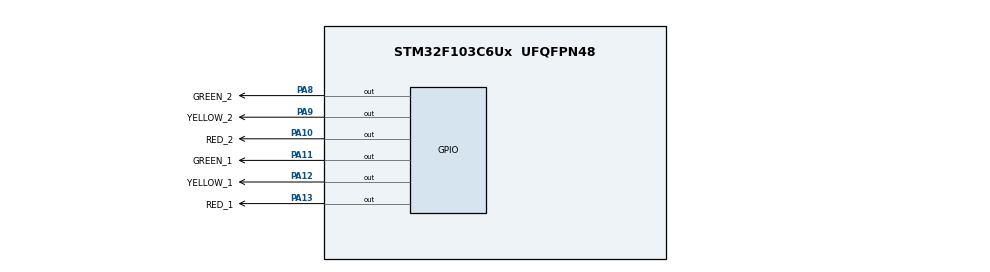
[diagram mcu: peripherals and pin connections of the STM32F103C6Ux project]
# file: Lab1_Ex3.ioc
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Mcu.Family=STM32F1
Mcu.Name=STM32F103C6Ux
Mcu.Package=UFQFPN48
NVIC.PriorityGroup=NVIC_PRIORITYGROUP_4
PA10.GPIO_Label=RED_2
PA10.Signal=GPIO_Output
PA11.GPIO_Label=GREEN_1
PA11.Signal=GPIO_Output
PA12.GPIO_Label=YELLOW_1
PA12.Signal=GPIO_Output
PA13.GPIO_Label=RED_1
PA13.Signal=GPIO_Output
PA8.GPIO_Label=GREEN_2
PA8.Signal=GPIO_Output
PA9.GPIO_Label=YELLOW_2
PA9.Signal=GPIO_Output
ProjectManager.HeapSize=0x200
ProjectManager.StackSize=0x400
ProjectManager.TargetToolchain=STM32CubeIDE
RCC.APB1Freq_Value=8000000
RCC.APB2Freq_Value=8000000
VP_SYS_VS_ND.Mode=No_Debug
board=custom

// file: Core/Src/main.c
/* USER CODE BEGIN Header */
/**
  ******************************************************************************
  * @file           : main.c
  * @brief          : Main program body
  ******************************************************************************
  * @attention
  *
  * <h2><center>&copy; Copyright (c) 2023 STMicroelectronics.
  * All rights reserved.</center></h2>
  *
  * This software component is licensed by ST under BSD 3-Clause license,
  * the "License"; You may not use this file except in compliance with the
  * License. You may obtain a copy of the License at:
  *                        opensource.org/licenses/BSD-3-Clause
  *
  ******************************************************************************
  */
/* USER CODE END Header */
#include "main.h"

void SystemClock_Config(void);
static void MX_GPIO_Init(void);

int main(void)
{

  /* MCU Configuration--------------------------------------------------------*/

  /* Reset of all peripherals, Initializes the Flash interface and the Systick. */
  HAL_Init();

  /* Configure the system clock */
  SystemClock_Config();

  /* Initialize all configured peripherals */
  MX_GPIO_Init();
  /* USER CODE BEGIN 2 */
  HAL_GPIO_WritePin ( GPIOA , GPIO_PIN_13 , GPIO_PIN_RESET ) ;//red1
  HAL_GPIO_WritePin ( GPIOA , GPIO_PIN_12 , GPIO_PIN_SET ) ;//yellow1
  HAL_GPIO_WritePin ( GPIOA , GPIO_PIN_11 , GPIO_PIN_SET ) ;//green1
  HAL_GPIO_WritePin ( GPIOA , GPIO_PIN_10 , GPIO_PIN_SET ) ;//red2
  HAL_GPIO_WritePin ( GPIOA , GPIO_PIN_9 , GPIO_PIN_SET ) ;//yellow2
  HAL_GPIO_WritePin ( GPIOA , GPIO_PIN_8 , GPIO_PIN_RESET ) ;//green2
   int count_1 = 5;
   int count_2 = 3;
   /* USER CODE END 2 */
   /* Infinite loop */
   /* USER CODE BEGIN WHILE */
   while (1)
   {
 	   if(count_1==0){
 		  GPIO_PinState pa13State = HAL_GPIO_ReadPin(GPIOA, GPIO_PIN_13);
 		  GPIO_PinState pa12State = HAL_GPIO_ReadPin(GPIOA, GPIO_PIN_12);
 		  GPIO_PinState pa11State = HAL_GPIO_ReadPin(GPIOA, GPIO_PIN_11);

 		  if (pa13State == GPIO_PIN_RESET){
 			  HAL_GPIO_TogglePin ( GPIOA , GPIO_PIN_13 | GPIO_PIN_11 );
 			  count_1 = 3;
 		  }
 		  if (pa12State == GPIO_PIN_RESET){
 			  HAL_GPIO_TogglePin ( GPIOA , GPIO_PIN_12 | GPIO_PIN_13 );
 			  count_1 = 5;
 		  }
 		  if (pa11State == GPIO_PIN_RESET){
 			  HAL_GPIO_TogglePin ( GPIOA , GPIO_PIN_11 | GPIO_PIN_12 );
 			  count_1 = 2;
 		  }
 	   }

 	 	   if(count_2==0){

 	 		  GPIO_PinState pa10State = HAL_GPIO_ReadPin(GPIOA, GPIO_PIN_10);
 	 		  GPIO_PinState pa9State = HAL_GPIO_ReadPin(GPIOA, GPIO_PIN_9);
 	 		  GPIO_PinState pa8State = HAL_GPIO_ReadPin(GPIOA, GPIO_PIN_8);

 	 		  if (pa10State == GPIO_PIN_RESET){
 	 			  HAL_GPIO_TogglePin ( GPIOA , GPIO_PIN_10 | GPIO_PIN_8 );
 	 			  count_2 = 3;
 	 		  }
 	 		  if (pa9State == GPIO_PIN_RESET){
 	 			  HAL_GPIO_TogglePin ( GPIOA , GPIO_PIN_9 | GPIO_PIN_10 );
 	 			  count_2 = 5;
 	 		  }
 	 		  if (pa8State == GPIO_PIN_RESET){
 	 			  HAL_GPIO_TogglePin ( GPIOA , GPIO_PIN_8 | GPIO_PIN_9 );
 	 			  count_2 = 2;
 	 		  }
 	   }
       count_1 = count_1 - 1 ;
       count_2 = count_2 - 1 ;
 	   HAL_Delay (1000) ;
   }
}

void SystemClock_Config(void)
{
  RCC_OscInitTypeDef RCC_OscInitStruct = {0};
  RCC_ClkInitTypeDef RCC_ClkInitStruct = {0};

  /** Initializes the RCC Oscillators according to the specified parameters
  * in the RCC_OscInitTypeDef structure.
  */
  RCC_OscInitStruct.OscillatorType = RCC_OSCILLATORTYPE_HSI;
  RCC_OscInitStruct.HSIState = RCC_HSI_ON;
  RCC_OscInitStruct.HSICalibrationValue = RCC_HSICALIBRATION_DEFAULT;
  RCC_OscInitStruct.PLL.PLLState = RCC_PLL_NONE;
  if (HAL_RCC_OscConfig(&RCC_OscInitStruct) != HAL_OK)
  {
    Error_Handler();
  }
  /** Initializes the CPU, AHB and APB buses clocks
  */
  RCC_ClkInitStruct.ClockType = RCC_CLOCKTYPE_HCLK|RCC_CLOCKTYPE_SYSCLK
                              |RCC_CLOCKTYPE_PCLK1|RCC_CLOCKTYPE_PCLK2;
  RCC_ClkInitStruct.SYSCLKSource = RCC_SYSCLKSOURCE_HSI;
  RCC_ClkInitStruct.AHBCLKDivider = RCC_SYSCLK_DIV1;
  RCC_ClkInitStruct.APB1CLKDivider = RCC_HCLK_DIV1;
  RCC_ClkInitStruct.APB2CLKDivider = RCC_HCLK_DIV1;

  if (HAL_RCC_ClockConfig(&RCC_ClkInitStruct, FLASH_LATENCY_0) != HAL_OK)
  {
    Error_Handler();
  }
}

static void MX_GPIO_Init(void)
{
  GPIO_InitTypeDef GPIO_InitStruct = {0};

  /* GPIO Ports Clock Enable */
  __HAL_RCC_GPIOA_CLK_ENABLE();
  __HAL_RCC_GPIOB_CLK_ENABLE();

  /*Configure GPIO pin Output Level */
  HAL_GPIO_WritePin(GPIOA, RED_1_Pin|YELLOW_1_Pin|GREEN_1_Pin|RED_2_Pin
                          |YELLOW_2_Pin, GPIO_PIN_RESET);

  /*Configure GPIO pin Output Level */
  HAL_GPIO_WritePin(GREEN_2_GPIO_Port, GREEN_2_Pin, GPIO_PIN_RESET);

  /*Configure GPIO pins : RED_1_Pin YELLOW_1_Pin GREEN_1_Pin RED_2_Pin
                           YELLOW_2_Pin */
  GPIO_InitStruct.Pin = RED_1_Pin|YELLOW_1_Pin|GREEN_1_Pin|RED_2_Pin
                          |YELLOW_2_Pin;
  GPIO_InitStruct.Mode = GPIO_MODE_OUTPUT_PP;
  GPIO_InitStruct.Pull = GPIO_NOPULL;
  GPIO_InitStruct.Speed = GPIO_SPEED_FREQ_LOW;
  HAL_GPIO_Init(GPIOA, &GPIO_InitStruct);

  /*Configure GPIO pin : GREEN_2_Pin */
  GPIO_InitStruct.Pin = GREEN_2_Pin;
  GPIO_InitStruct.Mode = GPIO_MODE_OUTPUT_PP;
  GPIO_InitStruct.Pull = GPIO_NOPULL;
  GPIO_InitStruct.Speed = GPIO_SPEED_FREQ_LOW;
  HAL_GPIO_Init(GREEN_2_GPIO_Port, &GPIO_InitStruct);

}

void Error_Handler(void)
{
  __disable_irq();
  while (1)
  {
  }
}

/************************ (C) COPYRIGHT STMicroelectronics *****END OF FILE****/
